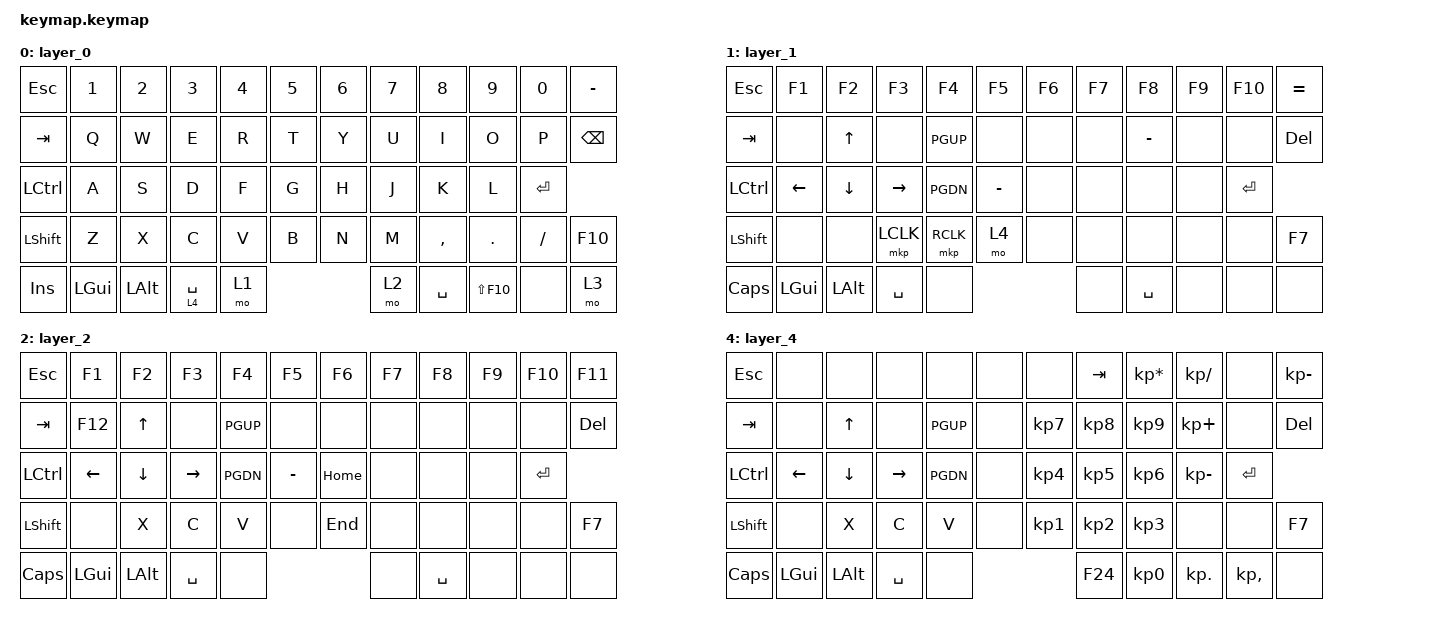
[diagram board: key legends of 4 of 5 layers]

#include <behaviors.dtsi>
#include <dt-bindings/zmk/keys.h>
#include <dt-bindings/zmk/mouse.h>
#include <dt-bindings/zmk/bt.h>

/ {
    keymap {
        compatible = "zmk,keymap";

        layer_0 {
            bindings =<
            //  [Col_L1]        [Col_L2]        [Col_L3]        [Col_L4]        [Col_L5]        [Col_L6]               [Col_R1]        [Col_R2]        [Col_R3]        [Col_R4]        [Col_R5]        [Col_R6]
                &kp ESC         &kp N1          &kp N2          &kp N3          &kp N4          &kp N5                 &kp N6          &kp N7          &kp N8          &kp N9          &kp N0          &kp MINUS      
				&kp TAB         &kp Q           &kp W           &kp E           &kp R           &kp T                  &kp Y           &kp U           &kp I           &kp O           &kp P           &kp BSPC       
				&kp LCTRL       &kp A           &kp S           &kp D           &kp F           &kp G                  &kp H           &kp J           &kp K           &kp L                   &kp ENTER      
 				&kp LSHFT       &kp Z           &kp X           &kp C           &kp V           &kp B                  &kp N           &kp M           &kp COMMA       &kp DOT         &kp FSLH        &kp F10        
				&kp INSERT      &kp LGUI        &kp LALT                     &lt 4 SPACE        &mo 1                  &mo 2                   &kp SPACE               &kp LS(F10)     &none           &mo 3          
            >;
        };

        layer_1 {
            bindings =<
            //  [Col_L1]        [Col_L2]        [Col_L3]        [Col_L4]        [Col_L5]        [Col_L6]               [Col_R1]        [Col_R2]        [Col_R3]        [Col_R4]        [Col_R5]        [Col_R6]
                &kp ESC         &kp F1          &kp F2          &kp F3          &kp F4          &kp F5                 &kp F6          &kp F7          &kp F8          &kp F9          &kp F10         &kp EQUAL      
				&kp TAB         &none           &kp UP          &none           &kp PGUP        &none                  &none           &none           &kp MINUS       &none           &none           &kp DELETE     
				&kp LCTRL       &kp LEFT        &kp DOWN        &kp RIGHT       &kp PGDN        &kp MINUS              &none           &none           &none           &none                   &kp ENTER      
 				&kp LSHFT       &none           &none           &mkp LCLK       &mkp RCLK       &mo 4                  &none           &none           &none           &none           &none           &kp F7         
				&kp CAPS        &kp LGUI        &kp LALT                     &kp SPACE          &none                  &none                   &kp SPACE               &none           &none           &none          
            >;
        };

        layer_2 {
            bindings =<
            //  [Col_L1]        [Col_L2]        [Col_L3]        [Col_L4]        [Col_L5]        [Col_L6]               [Col_R1]        [Col_R2]        [Col_R3]        [Col_R4]        [Col_R5]        [Col_R6]
                &kp ESC         &kp F1          &kp F2          &kp F3          &kp F4          &kp F5                 &kp F6          &kp F7          &kp F8          &kp F9          &kp F10         &kp F11        
				&kp TAB         &kp F12         &kp UP          &none           &kp PGUP        &none                  &none           &none           &none           &none           &none           &kp DELETE     
				&kp LCTRL       &kp LEFT        &kp DOWN        &kp RIGHT       &kp PGDN        &kp MINUS              &kp HOME        &none           &none           &none                   &kp ENTER      
 				&kp LSHFT       &none           &kp X           &kp C           &kp V           &none                  &kp END         &none           &none           &none           &none           &kp F7         
				&kp CAPS        &kp LGUI        &kp LALT                     &kp SPACE          &none                  &none                   &kp SPACE               &none           &none           &none          
            >;
        };

        layer_3 {
            bindings =<
            //  [Col_L1]        [Col_L2]        [Col_L3]        [Col_L4]        [Col_L5]        [Col_L6]               [Col_R1]        [Col_R2]        [Col_R3]        [Col_R4]        [Col_R5]        [Col_R6]
                &kp ESC         &kp F13         &kp F14         &kp F15         &kp F16         &kp F17                &kp F18         &kp F19         &kp F20         &kp F21         &kp F22         &kp F23        
				&kp TAB         &kp F18         &kp F19         &kp F20         &kp F21         &kp F22                &none           &none           &none           &none           &kp F24         &kp DELETE     
				&none           &kp F23         &kp F24         &none           &none           &none                  &none           &none           &none           &none                   &kp ENTER      
 				&none           &bt BT_SEL 0    &bt BT_SEL 1    &bt BT_SEL 2    &bt BT_SEL 3    &bt BT_CLR &none       &none           &none           &none           &none           &kp F7          &kp CAPS       
				&kp LGUI        &kp LALT        &kp SPACE                    &none              &none                  &kp F24                 &none                   &none           &none           &none          
            >;
        };

        layer_4 {
            bindings =<
            //  [Col_L1]        [Col_L2]        [Col_L3]        [Col_L4]        [Col_L5]        [Col_L6]               [Col_R1]        [Col_R2]        [Col_R3]        [Col_R4]        [Col_R5]        [Col_R6]
                &kp ESC         &none           &none           &none           &none           &none                  &none           &kp TAB         &kp KP_ASTERISK &kp KP_SLASH    &none           &kp KP_MINUS   
				&kp TAB         &none           &kp UP          &none           &kp PGUP        &none                  &kp KP_N7       &kp KP_N8       &kp KP_N9       &kp KP_PLUS     &none           &kp DELETE     
				&kp LCTRL       &kp LEFT        &kp DOWN        &kp RIGHT       &kp PGDN        &none                  &kp KP_N4       &kp KP_N5       &kp KP_N6       &kp KP_MINUS            &kp ENTER      
 				&kp LSHFT       &none           &kp X           &kp C           &kp V           &none                  &kp KP_N1       &kp KP_N2       &kp KP_N3       &none           &none           &kp F7         
				&kp CAPS        &kp LGUI        &kp LALT                     &kp SPACE          &none                  &kp F24                 &kp KP_N0               &kp KP_DOT      &kp KP_COMMA    &none          
            >;
        };
    };
};

/ {
    combos {
        compatible = "zmk,combos";
        //  0  1  2  3  4  5      6  7  8  9 10 11
        // 12 13 14 15 16 17     18 19 20 21 22 23 
        // 24 25 26 27 28 29     30 31 32 33  34
        // 35 36 37 38 39 40     41 42 43 44 45 46
        // 47 48 49 50  51       52  53   54 55 56    

        combo_LBKT {
            timeout-ms = <35>;
            key-positions = <15 16>;
            bindings = <&kp LBKT>;
        };
        combo_RBKT {
            timeout-ms = <50>;
            key-positions = <16 17>;
            bindings = <&kp RBKT>;
        };
        combo_LS_LBKT {
            timeout-ms = <50>;
            key-positions = <18 19>;
            bindings = <&kp LS(LBKT)>;
        };
        combo_LS_RBKT {
            timeout-ms = <50>;
            key-positions = <19 20>;
            bindings = <&kp LS(RBKT)>;
        };
        combo_SEMI {
            timeout-ms = <50>;
            key-positions = <27 28>;
            bindings = <&kp SEMI>;
        };
        combo_LS_SEMI {
            timeout-ms = <50>;
            key-positions = <28 29>;
            bindings = <&kp LS(SEMI)>;
        };
        combo_SQT {
            timeout-ms = <50>;
            key-positions = <30 31>;
            bindings = <&kp SQT>;
        };
        combo_LS_SQT {
            timeout-ms = <50>;
            key-positions = <31 32>;
            bindings = <&kp LS(SQT)>;
        };
    };
};
